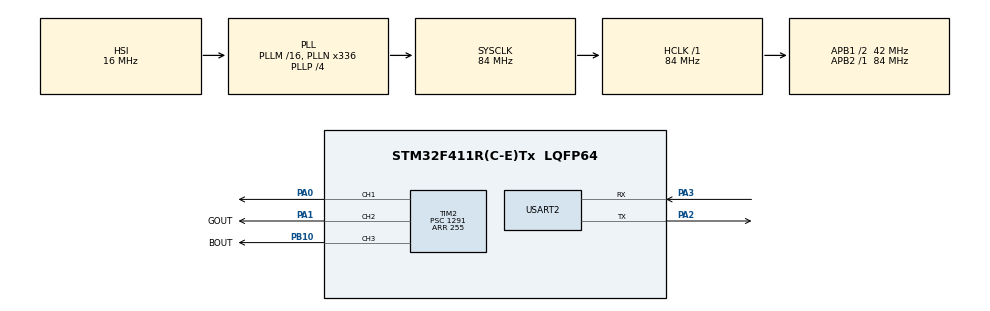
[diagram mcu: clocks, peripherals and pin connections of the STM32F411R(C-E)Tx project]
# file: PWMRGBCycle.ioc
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Mcu.Family=STM32F4
Mcu.Name=STM32F411R(C-E)Tx
Mcu.Package=LQFP64
NVIC.PriorityGroup=NVIC_PRIORITYGROUP_0
PA0-WKUP.Signal=S_TIM2_CH1_ETR
PA1.GPIO_Label=GOUT
PA1.Signal=S_TIM2_CH2
PA2.Mode=Asynchronous
PA2.Signal=USART2_TX
PA3.Mode=Asynchronous
PA3.Signal=USART2_RX
PB10.GPIO_Label=BOUT
PB10.Signal=S_TIM2_CH3
ProjectManager.HeapSize=0x200
ProjectManager.StackSize=0x400
ProjectManager.TargetToolchain=CMake
RCC.48MHZClocksFreq_Value=84000000
RCC.AHBFreq_Value=84000000
RCC.APB1CLKDivider=RCC_HCLK_DIV2
RCC.APB1Freq_Value=42000000
RCC.APB1TimFreq_Value=84000000
RCC.APB2Freq_Value=84000000
RCC.APB2TimFreq_Value=84000000
RCC.CortexFreq_Value=84000000
RCC.FLatency-AdvancedSettings=FLASH_LATENCY_2
RCC.HCLKFreq_Value=84000000
RCC.HSE_VALUE=8000000
RCC.HSI_VALUE=16000000
RCC.PLLN=336
RCC.PLLP=RCC_PLLP_DIV4
RCC.SYSCLKFreq_VALUE=84000000
RCC.SYSCLKSource=RCC_SYSCLKSOURCE_PLLCLK
RCC.VCOOutputFreq_Value=336000000
SH.S_TIM2_CH1_ETR.0=TIM2_CH1,PWM Generation1 CH1
SH.S_TIM2_CH2.0=TIM2_CH2,PWM Generation2 CH2
SH.S_TIM2_CH3.0=TIM2_CH3,PWM Generation3 CH3
TIM2.Channel-PWM\ Generation1\ CH1=TIM_CHANNEL_1
TIM2.Channel-PWM\ Generation2\ CH2=TIM_CHANNEL_2
TIM2.Channel-PWM\ Generation3\ CH3=TIM_CHANNEL_3
TIM2.Period=255
TIM2.Prescaler=1291
USART2.VirtualMode=VM_ASYNC
VP_TIM2_VS_ClockSourceINT.Mode=Internal
board=NUCLEO-F411RE

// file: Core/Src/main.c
/* USER CODE BEGIN Header */
/**
  ******************************************************************************
  * @file           : main.c
  * @brief          : Main program body
  ******************************************************************************
  * @attention
  *
  * Copyright (c) 2024 STMicroelectronics.
  * All rights reserved.
  *
  * This software is licensed under terms that can be found in the LICENSE file
  * in the root directory of this software component.
  * If no LICENSE file comes with this software, it is provided AS-IS.
  *
  ******************************************************************************
  */
/* USER CODE END Header */
#include "main.h"
#include <stdio.h>

#ifdef __GNUC__
  #define PUTCHAR_PROTOTYPE int __io_putchar(int ch)
#else
  #define PUTCHAR_PROTOTYPE int fputc(int ch, FILE *f)
#endif

UART_HandleTypeDef huart2;

PUTCHAR_PROTOTYPE {
  HAL_UART_Transmit(&huart2, (uint8_t *)&ch, 1, HAL_MAX_DELAY);
  return ch;
}

TIM_HandleTypeDef htim2;

UART_HandleTypeDef huart2;

void SystemClock_Config(void);
static void MX_GPIO_Init(void);
static void MX_TIM2_Init(void);
static void MX_USART2_UART_Init(void);

/* USER CODE BEGIN 0 */
void setRgb(uint8_t r, uint8_t g, uint8_t b) {
  htim2.Instance->CCR1 = r;
  htim2.Instance->CCR2 = g;
  htim2.Instance->CCR3 = b;
  printf("RGB=(%03d,%03d,%03d)\r\n", r, g, b);
}

/* USER CODE END 0 */

int main(void)
{

  /* MCU Configuration--------------------------------------------------------*/

  /* Reset of all peripherals, Initializes the Flash interface and the Systick. */
  HAL_Init();

  /* Configure the system clock */
  SystemClock_Config();

  /* Initialize all configured peripherals */
  MX_GPIO_Init();
  MX_TIM2_Init();
  MX_USART2_UART_Init();
  /* USER CODE BEGIN 2 */

  HAL_TIM_PWM_Start(&htim2, TIM_CHANNEL_1);
  HAL_TIM_PWM_Start(&htim2, TIM_CHANNEL_2);
  HAL_TIM_PWM_Start(&htim2, TIM_CHANNEL_3);

  /* USER CODE END 2 */

  /* Infinite loop */
  /* USER CODE BEGIN WHILE */
  // MUST be > uint8_t if using ARR as 255. uint8_t rollover from 255 -> 0 will prevent outer loops from executing
  uint16_t r;
  uint16_t g;
  uint16_t b;

  while (1)
  {
    /* USER CODE END WHILE */
    for(r = 0; r <= htim2.Instance->ARR; r += 50) {
      for(g = 0; g <= htim2.Instance->ARR; g += 50) {
        for(b = 0; b <= htim2.Instance->ARR; b += 50) {
          setRgb(r, g, b);
          HAL_Delay(50);
        }
      }
    }
  }
}

void SystemClock_Config(void)
{
  RCC_OscInitTypeDef RCC_OscInitStruct = {0};
  RCC_ClkInitTypeDef RCC_ClkInitStruct = {0};

  /** Configure the main internal regulator output voltage
  */
  __HAL_RCC_PWR_CLK_ENABLE();
  __HAL_PWR_VOLTAGESCALING_CONFIG(PWR_REGULATOR_VOLTAGE_SCALE1);

  /** Initializes the RCC Oscillators according to the specified parameters
  * in the RCC_OscInitTypeDef structure.
  */
  RCC_OscInitStruct.OscillatorType = RCC_OSCILLATORTYPE_HSI;
  RCC_OscInitStruct.HSIState = RCC_HSI_ON;
  RCC_OscInitStruct.HSICalibrationValue = RCC_HSICALIBRATION_DEFAULT;
  RCC_OscInitStruct.PLL.PLLState = RCC_PLL_ON;
  RCC_OscInitStruct.PLL.PLLSource = RCC_PLLSOURCE_HSI;
  RCC_OscInitStruct.PLL.PLLM = 16;
  RCC_OscInitStruct.PLL.PLLN = 336;
  RCC_OscInitStruct.PLL.PLLP = RCC_PLLP_DIV4;
  RCC_OscInitStruct.PLL.PLLQ = 4;
  if (HAL_RCC_OscConfig(&RCC_OscInitStruct) != HAL_OK)
  {
    Error_Handler();
  }

  /** Initializes the CPU, AHB and APB buses clocks
  */
  RCC_ClkInitStruct.ClockType = RCC_CLOCKTYPE_HCLK|RCC_CLOCKTYPE_SYSCLK
                              |RCC_CLOCKTYPE_PCLK1|RCC_CLOCKTYPE_PCLK2;
  RCC_ClkInitStruct.SYSCLKSource = RCC_SYSCLKSOURCE_PLLCLK;
  RCC_ClkInitStruct.AHBCLKDivider = RCC_SYSCLK_DIV1;
  RCC_ClkInitStruct.APB1CLKDivider = RCC_HCLK_DIV2;
  RCC_ClkInitStruct.APB2CLKDivider = RCC_HCLK_DIV1;

  if (HAL_RCC_ClockConfig(&RCC_ClkInitStruct, FLASH_LATENCY_2) != HAL_OK)
  {
    Error_Handler();
  }
}

static void MX_TIM2_Init(void)
{

  TIM_ClockConfigTypeDef sClockSourceConfig = {0};
  TIM_MasterConfigTypeDef sMasterConfig = {0};
  TIM_OC_InitTypeDef sConfigOC = {0};

  htim2.Instance = TIM2;
  htim2.Init.Prescaler = 1291;
  htim2.Init.CounterMode = TIM_COUNTERMODE_UP;
  htim2.Init.Period = 255;
  htim2.Init.ClockDivision = TIM_CLOCKDIVISION_DIV1;
  htim2.Init.AutoReloadPreload = TIM_AUTORELOAD_PRELOAD_DISABLE;
  if (HAL_TIM_Base_Init(&htim2) != HAL_OK)
  {
    Error_Handler();
  }
  sClockSourceConfig.ClockSource = TIM_CLOCKSOURCE_INTERNAL;
  if (HAL_TIM_ConfigClockSource(&htim2, &sClockSourceConfig) != HAL_OK)
  {
    Error_Handler();
  }
  if (HAL_TIM_PWM_Init(&htim2) != HAL_OK)
  {
    Error_Handler();
  }
  sMasterConfig.MasterOutputTrigger = TIM_TRGO_RESET;
  sMasterConfig.MasterSlaveMode = TIM_MASTERSLAVEMODE_DISABLE;
  if (HAL_TIMEx_MasterConfigSynchronization(&htim2, &sMasterConfig) != HAL_OK)
  {
    Error_Handler();
  }
  sConfigOC.OCMode = TIM_OCMODE_PWM1;
  sConfigOC.Pulse = 0;
  sConfigOC.OCPolarity = TIM_OCPOLARITY_HIGH;
  sConfigOC.OCFastMode = TIM_OCFAST_DISABLE;
  if (HAL_TIM_PWM_ConfigChannel(&htim2, &sConfigOC, TIM_CHANNEL_1) != HAL_OK)
  {
    Error_Handler();
  }
  if (HAL_TIM_PWM_ConfigChannel(&htim2, &sConfigOC, TIM_CHANNEL_2) != HAL_OK)
  {
    Error_Handler();
  }
  if (HAL_TIM_PWM_ConfigChannel(&htim2, &sConfigOC, TIM_CHANNEL_3) != HAL_OK)
  {
    Error_Handler();
  }
  HAL_TIM_MspPostInit(&htim2);

}

static void MX_USART2_UART_Init(void)
{

  huart2.Instance = USART2;
  huart2.Init.BaudRate = 115200;
  huart2.Init.WordLength = UART_WORDLENGTH_8B;
  huart2.Init.StopBits = UART_STOPBITS_1;
  huart2.Init.Parity = UART_PARITY_NONE;
  huart2.Init.Mode = UART_MODE_TX_RX;
  huart2.Init.HwFlowCtl = UART_HWCONTROL_NONE;
  huart2.Init.OverSampling = UART_OVERSAMPLING_16;
  if (HAL_UART_Init(&huart2) != HAL_OK)
  {
    Error_Handler();
  }

}

static void MX_GPIO_Init(void)
{

  /* GPIO Ports Clock Enable */
  __HAL_RCC_GPIOA_CLK_ENABLE();
  __HAL_RCC_GPIOB_CLK_ENABLE();

}

void Error_Handler(void)
{
  __disable_irq();
  while (1)
  {
  }
}
